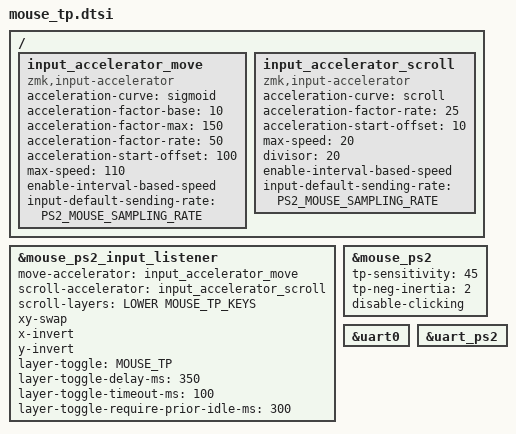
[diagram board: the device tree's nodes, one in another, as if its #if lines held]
#ifdef HAS_MOUSE_TP
  #include <dt-bindings/zmk/mouse.h>
  #include <dt-bindings/zmk/mouse_settings.h>
  #include <behaviors/mouse_keys.dtsi>
  #include <behaviors/mouse_setting.dtsi>

  // ランタイム設定・リセット用キーコード定義
  #define U_MSS_TP_S_I  &mms MS_TP_SENSITIVITY_INCR
  #define U_MSS_TP_S_D  &mms MS_TP_SENSITIVITY_DECR
  #define U_MSS_TP_V6_I &mms MS_TP_VALUE6_INCR
  #define U_MSS_TP_V6_D &mms MS_TP_VALUE6_DECR
  #define U_MSS_TP_NI_I &mms MS_TP_NEG_INERTIA_INCR
  #define U_MSS_TP_NI_D &mms MS_TP_NEG_INERTIA_DECR
  #define U_MSS_TP_PT_I &mms MS_TP_PTS_THRESHOLD_INCR
  #define U_MSS_TP_PT_D &mms MS_TP_PTS_THRESHOLD_DECR
  #define U_MSS_RESET   &mms MS_RESET
  #define U_MSS_LOG     &mms MS_LOG

  #ifdef MOUSE_PS2_DT_PRESENT
    #define PS2_MOUSE_SAMPLING_RATE 100

    / {
        input_accelerator_move: input_accelerator_move {
          status = "okay";
          compatible = "zmk,input-accelerator";
          acceleration-curve = "sigmoid";
          acceleration-factor-base = <10>;    // ★30 -> 10: 静止時の微小ドリフトを1/3に圧縮
          acceleration-factor-max = <150>;    // ★140 -> 150: 指で倒した時の最高速を補強
          acceleration-factor-rate = <50>;    // ★40 -> 50: 一定の力を超えた後の立ち上がりを良くする
          acceleration-start-offset = <100>;  // ★60 -> 100: 不感帯（デッドゾーン）を広くして勝手に動かないようにする
          max-speed = <110>;
          enable-interval-based-speed;
          input-default-sending-rate = <PS2_MOUSE_SAMPLING_RATE>;
        };

        input_accelerator_scroll: input_accelerator_scroll {
          status = "okay";
          compatible = "zmk,input-accelerator";
          acceleration-curve = "scroll";
          acceleration-factor-rate = <25>;
          acceleration-start-offset = <10>;
          max-speed = <20>;
          divisor = <20>;
          enable-interval-based-speed;
          input-default-sending-rate = <PS2_MOUSE_SAMPLING_RATE>;
        };
    };

    &mouse_ps2_input_listener {
      status = "okay";
      move-accelerator = <&input_accelerator_move>;
      scroll-accelerator = <&input_accelerator_scroll>;
      scroll-layers = <LOWER MOUSE_TP_KEYS>;
      xy-swap;
      x-invert;
      y-invert;
      layer-toggle = <MOUSE_TP>;
      layer-toggle-delay-ms = <350>;               // ★300 -> 350: ドリフトでマウスレイヤーが誤爆するのを防ぐ
      layer-toggle-timeout-ms = <100>;             // ★125 -> 100: 操作終了後すぐに通常レイヤーへ戻す
      layer-toggle-require-prior-idle-ms = <300>;
    };

    &mouse_ps2 {
      status = "okay";
      tp-sensitivity = <45>;   // ★60 -> 45: センサー自体の感度を少し下げてノイズを拾いにくくする
      tp-neg-inertia = <2>;    // ★追加: 指を離した直後の「揺り戻しドリフト」を抑える（デフォルト6）
      disable-clicking;
    };

    #ifdef MOUSE_PS2_DRIVER_UART
      &uart0 { status = "okay"; };
      &uart_ps2 { status = "okay"; };
    #else
      &gpio_ps2 { status = "okay"; };
    #endif
  #endif
#endif
